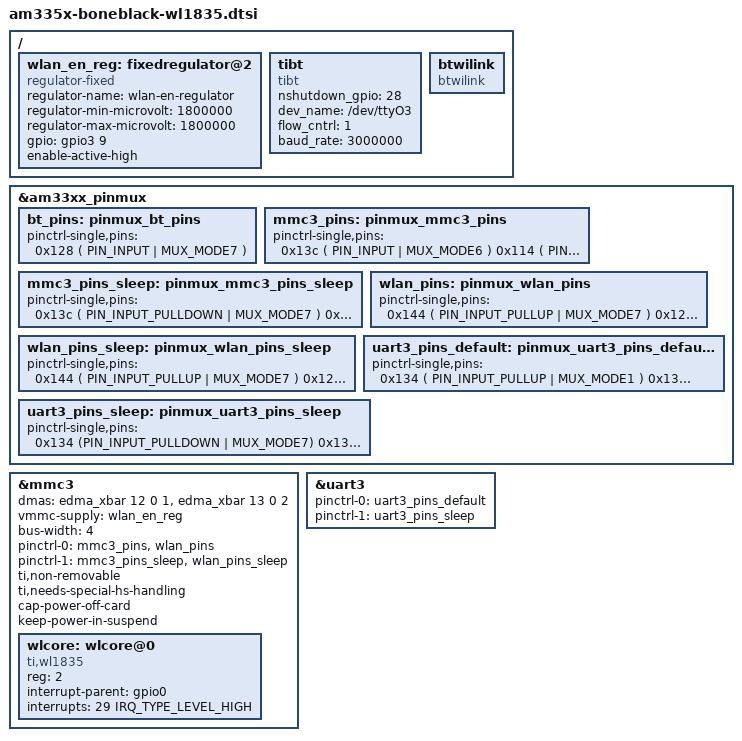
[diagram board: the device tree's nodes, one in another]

#include <dt-bindings/interrupt-controller/irq.h>

/ {
	wlan_en_reg: fixedregulator@2 {
		compatible = "regulator-fixed";
		regulator-name = "wlan-en-regulator";
		regulator-min-microvolt = <1800000>;
		regulator-max-microvolt = <1800000>;

		/* WL_EN */
		gpio = <&gpio3 9 0>;
		enable-active-high;
	};

	tibt {
		compatible = "tibt";
		nshutdown_gpio = <28>;
		dev_name = "/dev/ttyO3";
		flow_cntrl = <1>;
		baud_rate = <3000000>;
	};

	btwilink {
		compatible = "btwilink";
	};
};

&am33xx_pinmux {
	bt_pins: pinmux_bt_pins {
		pinctrl-single,pins = <
		0x128 ( PIN_INPUT | MUX_MODE7 ) /* (K17) gmii1_txd0.gpio0[28] - BT_EN */
		>;
	};

	mmc3_pins: pinmux_mmc3_pins {
		pinctrl-single,pins = <
		  0x13c ( PIN_INPUT | MUX_MODE6 ) /* (L15) gmii1_rxd1.mmc2_clk */
		  0x114 ( PIN_OUTPUT | MUX_MODE6 ) /* (J16) gmii1_txen.mmc2_cmd */
		  0x118 ( PIN_INPUT | MUX_MODE5 ) /* (J17) gmii1_rxdv.mmc2_dat0 */
		  0x11c ( PIN_INPUT | MUX_MODE5 ) /* (J18) gmii1_txd3.mmc2_dat1 */
		  0x120 ( PIN_INPUT | MUX_MODE5 ) /* (K15) gmii1_txd2.mmc2_dat2 */
		  0x108 ( PIN_INPUT | MUX_MODE5 ) /* (H16) gmii1_col.mmc2_dat3 */
		>;
	};

	mmc3_pins_sleep: pinmux_mmc3_pins_sleep {
		pinctrl-single,pins = <
		0x13c ( PIN_INPUT_PULLDOWN | MUX_MODE7 ) /* (L15) gmii1_rxd1.mmc2_clk */
		0x114 ( PIN_INPUT_PULLDOWN | MUX_MODE7 ) /* (J16) gmii1_txen.mmc2_cmd */
		0x118 ( PIN_INPUT_PULLDOWN | MUX_MODE7 ) /* (J17) gmii1_rxdv.mmc2_dat0 */
		0x11c ( PIN_INPUT_PULLDOWN | MUX_MODE7 ) /* (J18) gmii1_txd3.mmc2_dat1 */
		0x120 ( PIN_INPUT_PULLDOWN | MUX_MODE7 ) /* (K15) gmii1_txd2.mmc2_dat2 */
		0x108 ( PIN_INPUT_PULLDOWN | MUX_MODE7 ) /* (H16) gmii1_col.mmc2_dat3 */
		>;
	};

	/* wl18xx card enable/irq GPIOs. */
	wlan_pins: pinmux_wlan_pins {
		pinctrl-single,pins = <
		0x144 ( PIN_INPUT_PULLUP | MUX_MODE7 )  /* (H18) rmii1_refclk.gpio0[29] - WL_IRQ */
		0x12c ( PIN_OUTPUT_PULLUP | MUX_MODE7 ) /* (K18) gmii1_txclk.gpio3[9] - WL_EN */
		0x130 ( PIN_OUTPUT_PULLUP | MUX_MODE7 ) /* (L18) gmii1_rxclk.gpio3[10] - Cape_Buffer_EN */
		>;
	};

	/* wl18xx card enable/irq GPIOs. */
	wlan_pins_sleep: pinmux_wlan_pins_sleep {
		pinctrl-single,pins = <
		0x144 ( PIN_INPUT_PULLUP | MUX_MODE7 )  /* (H18) rmii1_refclk.gpio0[29] - WL_IRQ */
		0x12c ( PIN_OUTPUT_PULLUP | MUX_MODE7 ) /* (K18) gmii1_txclk.gpio3[9] - WL_EN */
		0x130 ( PIN_OUTPUT_PULLUP | MUX_MODE7 ) /* (L18) gmii1_rxclk.gpio3[10] - Cape_Buffer_EN */
		>;
	};

	uart3_pins_default: pinmux_uart3_pins_default {
		pinctrl-single,pins = <
			0x134 ( PIN_INPUT_PULLUP | MUX_MODE1 ) 		/* (L17) gmii1_rxd3.uart3_rxd */
			0x138 ( PIN_OUTPUT_PULLDOWN | MUX_MODE1 )	/* (L16) gmii1_rxd2.uart3_txd */
			0x148 ( PIN_INPUT | MUX_MODE3 ) 			    /* (M17) mdio_data.uart3_ctsn */
			0x14c ( PIN_OUTPUT_PULLDOWN | MUX_MODE3 ) /* (M18) mdio_clk.uart3_rtsn */
		>;
	};

	uart3_pins_sleep: pinmux_uart3_pins_sleep {
		pinctrl-single,pins = <
			0x134 (PIN_INPUT_PULLDOWN | MUX_MODE7)	/* (L17) gmii1_rxd3.uart3_rxd */
			0x138 (PIN_INPUT_PULLDOWN | MUX_MODE7)	/* (L16) gmii1_rxd2.uart3_txd */
			0x148 (PIN_INPUT_PULLDOWN | MUX_MODE7)	/* (M17) mdio_data.uart3_ctsn */
			0x14c (PIN_INPUT_PULLDOWN | MUX_MODE7)	/* (M18) mdio_clk.uart3_rtsn */

		>;
	};
};

&mmc3 {
	dmas = <&edma_xbar 12 0 1
		&edma_xbar 13 0 2>;
	dma-names = "tx", "rx";
	status = "okay";
	vmmc-supply = <&wlan_en_reg>;
	bus-width = <4>;
	pinctrl-names = "default", "sleep";
	pinctrl-0 = <&mmc3_pins &wlan_pins>;
	pinctrl-1 = <&mmc3_pins_sleep &wlan_pins_sleep>;
	ti,non-removable;
	ti,needs-special-hs-handling;
	cap-power-off-card;
	keep-power-in-suspend;

	#address-cells = <1>;
	#size-cells = <0>;
	wlcore: wlcore@0 {
		compatible = "ti,wl1835";
		reg = <2>;
		interrupt-parent = <&gpio0>;
		interrupts = <29 IRQ_TYPE_LEVEL_HIGH>;
	};
};

&uart3 {
	pinctrl-names = "default", "sleep";
	pinctrl-0 = <&uart3_pins_default>;
	pinctrl-1 = <&uart3_pins_sleep>;
	status = "okay";
};
